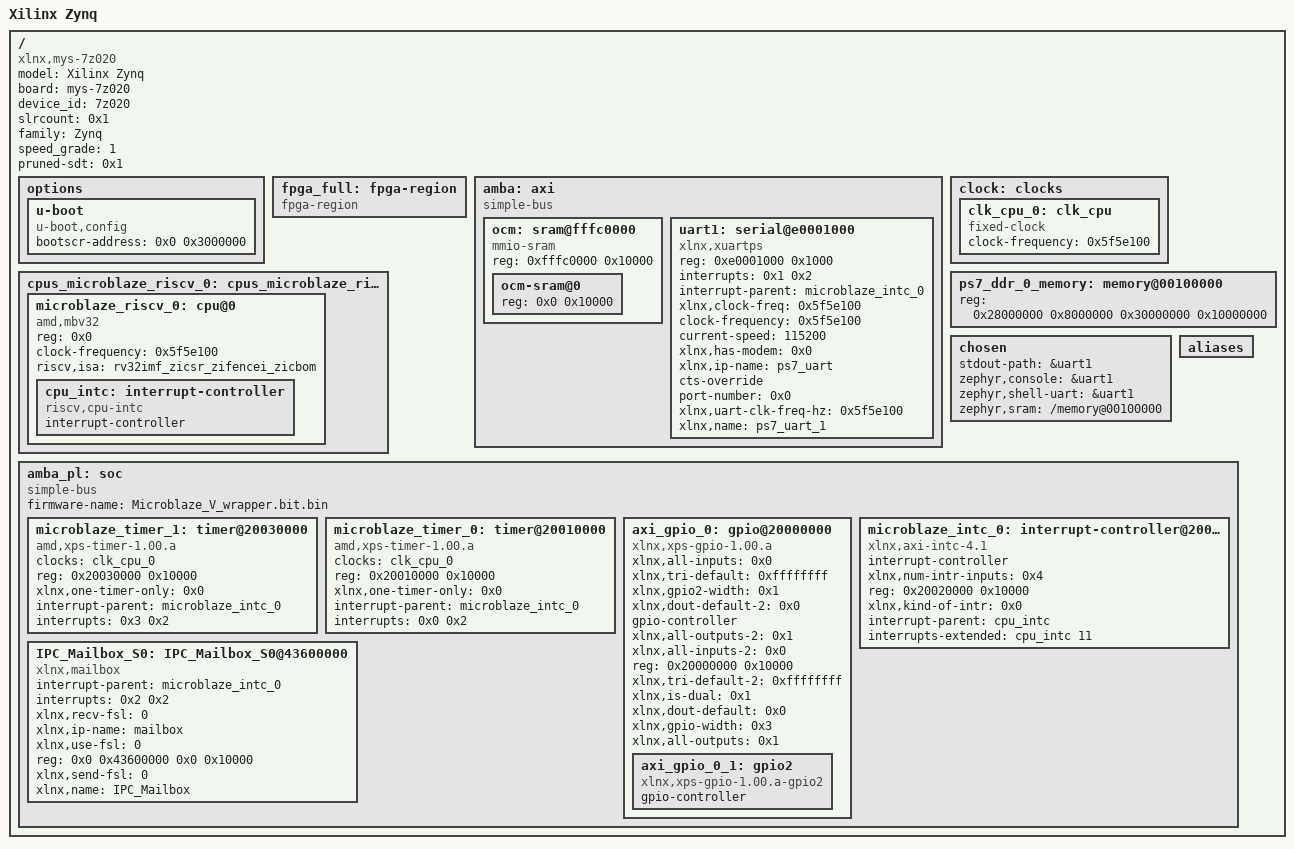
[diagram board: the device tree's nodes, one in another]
/*
 * Xilinx Zynq 7000 DTSI
 * Describes the hardware common to all Zynq 7000-based boards.
 *
 *  Copyright (C) 2011 - 2015 Xilinx
 * (C) Copyright 2022-2024 Advanced Micro Devices, Inc. All Rights Reserved.
 */

/dts-v1/;

/ {
        #address-cells = <0x1>;
        #size-cells = <0x1>;
        compatible = "xlnx,mys-7z020";
        model = "Xilinx Zynq";
        board = "mys-7z020";
        device_id = "7z020";
        slrcount = <0x1>;
        family = "Zynq";
        speed_grade = "1";
        pruned-sdt = <0x1>;

        options {

                u-boot {
                        compatible = "u-boot,config";
                        bootscr-address = <0x0 0x3000000>;
                };
        };

        fpga_full: fpga-region {
                compatible = "fpga-region";
                #address-cells = <0x1>;
                #size-cells = <0x1>;
                ranges;
                phandle = <0x3b>;
        };

        amba: axi {
                bootph-all;
                compatible = "simple-bus";
                #address-cells = <0x1>;
                #size-cells = <0x1>;
                ranges;
                phandle = <0x1>;

                ocm: sram@fffc0000 {
                        compatible = "mmio-sram";
                        reg = <0xfffc0000 0x10000>;
                        #address-cells = <0x1>;
                        #size-cells = <0x1>;
                        ranges = <0x0 0xfffc0000 0x10000>;
                        phandle = <0x3d>;

                        ocm-sram@0 {
                                reg = <0x0 0x10000>;
                        };
                };

                uart1: serial@e0001000 {
                        compatible = "xlnx,xuartps";
                        status = "okay";
                        clock-names = "uart_clk", "pclk";
                        reg = <0xe0001000 0x1000>;
                        interrupts = <0x1 0x2>;
                        interrupt-parent = <&microblaze_intc_0>;
                        xlnx,clock-freq = <0x5f5e100>;
                        clock-frequency = <0x5f5e100>;
                        current-speed = <115200>;
                        xlnx,has-modem = <0x0>;
                        xlnx,ip-name = "ps7_uart";
                        cts-override;
                        port-number = <0x0>;
                        xlnx,uart-clk-freq-hz = <0x5f5e100>;
                        xlnx,name = "ps7_uart_1";
                        phandle = <0x6>;
                };
        };

        cpus_microblaze_riscv_0: cpus_microblaze_riscv {
                #cpu-mask-cells = <0x1>;
                #address-cells = <0x1>;
                #size-cells = <0x0>;
                #ranges-address-cells = <0x1>;
                #ranges-size-cells = <0x1>;
                phandle = <0x51>;

                microblaze_riscv_0: cpu@0 {
                        reg = <0x0>;
                        clock-frequency = <0x5f5e100>;
                        compatible = "amd,mbv32", "riscv";
                        device_type = "cpu";
                        phandle = <0x52>;
                        riscv,isa = "rv32imf_zicsr_zifencei_zicbom";

                        cpu_intc: interrupt-controller {
                                compatible = "riscv,cpu-intc";
                                interrupt-controller;
                                #interrupt-cells = <0x1>;
                                phandle = <0x57>;
                        };
                };
        };

        clock: clocks {
                #address-cells = <0x1>;
                #size-cells = <0x0>;
                phandle = <0x53>;

                clk_cpu_0: clk_cpu {
                        compatible = "fixed-clock";
                        clock-frequency = <0x5f5e100>;
                        #clock-cells = <0x0>;
                        phandle = <0x54>;
                };
        };

        ps7_ddr_0_memory: memory@00100000 {
                device_type = "memory";
                reg = <0x28000000 0x8000000 0x30000000 0x10000000>;
                phandle = <0x2>;
        };

        chosen {
                stdout-path = &uart1;
                zephyr,console = &uart1;
                zephyr,shell-uart = &uart1;
                zephyr,sram = "/memory@00100000";
        };

        aliases {
        };

        amba_pl: soc {
                phandle = <0x39>;
                firmware-name = "Microblaze_V_wrapper.bit.bin";
                #size-cells = <0x1>;
                #address-cells = <0x1>;
                compatible = "simple-bus";
                ranges;

                microblaze_timer_1: timer@20030000 {
                        clocks = <&clk_cpu_0>;
                        reg = <0x20030000 0x10000>;
                        xlnx,one-timer-only = <0x0>;
                        interrupt-parent = <&microblaze_intc_0>;
                        compatible = "amd,xps-timer-1.00.a";
                        interrupts = <0x3 0x2>;
                        phandle = <0x4>;
                };

                microblaze_timer_0: timer@20010000 {
                        clocks = <&clk_cpu_0>;
                        reg = <0x20010000 0x10000>;
                        xlnx,one-timer-only = <0x0>;
                        interrupt-parent = <&microblaze_intc_0>;
                        compatible = "amd,xps-timer-1.00.a";
                        interrupts = <0x0 0x2>;
                        phandle = <0x10>;
                };

                axi_gpio_0: gpio@20000000 {
                        xlnx,all-inputs = <0x0>;
                        xlnx,tri-default = <0xffffffff>;
                        xlnx,gpio2-width = <0x1>;
                        xlnx,dout-default-2 = <0x0>;
                        gpio-controller;
                        xlnx,all-outputs-2 = <0x1>;
                        xlnx,all-inputs-2 = <0x0>;
                        reg = <0x20000000 0x10000>;
                        xlnx,tri-default-2 = <0xffffffff>;
                        xlnx,is-dual = <0x1>;
                        xlnx,dout-default = <0x0>;
                        xlnx,gpio-width = <0x3>;
                        #gpio-cells = <0x2>;
                        xlnx,all-outputs = <0x1>;
                        compatible = "xlnx,xps-gpio-1.00.a";
                        phandle = <0x11>;

                        axi_gpio_0_1: gpio2 {
                                #gpio-cells = <0x2>;
                                gpio-controller;
                                compatible = "xlnx,xps-gpio-1.00.a-gpio2";
                                phandle = <0x12>;
                        };
                };

                microblaze_intc_0: interrupt-controller@20020000 {
                        interrupt-controller;
                        xlnx,num-intr-inputs = <0x4>;
                        reg = <0x20020000 0x10000>;
                        compatible = "xlnx,axi-intc-4.1", "xlnx,xps-intc-1.00.a";
                        xlnx,kind-of-intr = <0x0>;
                        #interrupt-cells = <0x2>;
                        phandle = <0x3>;
                        interrupt-parent = <&cpu_intc>;
                        interrupts-extended = <&cpu_intc 11>;
                };

                IPC_Mailbox_S0: IPC_Mailbox_S0@43600000 {
			interrupt-parent = <&microblaze_intc_0>;
			interrupts = < 0x2 0x2 >;
			status = "okay";
			compatible = "xlnx,mailbox";
			xlnx,recv-fsl = <0>;
			xlnx,ip-name = "mailbox";
			xlnx,use-fsl = <0>;
			reg = <0x0 0x43600000 0x0 0x10000>;
			xlnx,send-fsl = <0>;
			xlnx,name = "IPC_Mailbox";
		};
        };
};
